# DEBUGSS_WRAP0_ROM_TABLE_0_1 register map
Vendor: Texas Instruments
Peripheral module from a debugger description file (folder am62P).
Registers are 32-bit, read-only, reset values left out (the file's numbers can be read two ways) unless marked. A register's access mark holds for its fields unless they carry their own. Offsets are as the file gives them; lines under a group give offsets from that group; [hi:lo] are bit positions; {n}, {i} and the like mark numbered series; 'fields as' and 'values as' point back to an identical list; <NAME> marks a mode.

## DEBUGSS_WRAP0_ROM_TABLE_0_1
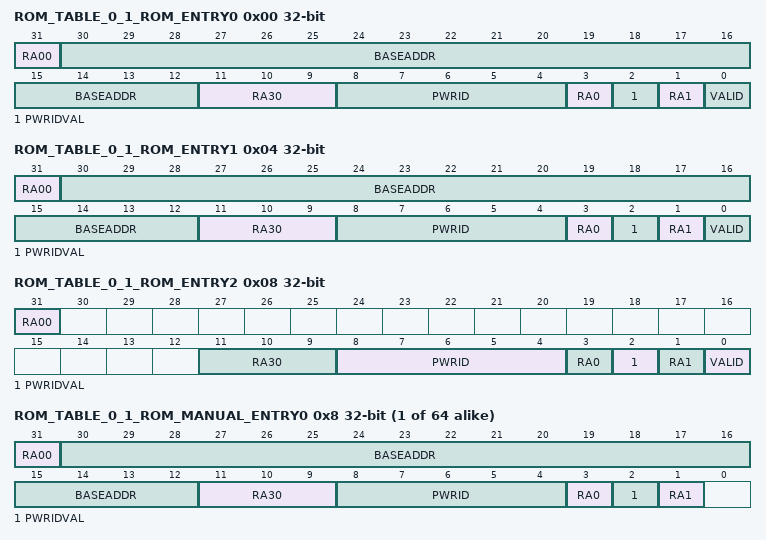
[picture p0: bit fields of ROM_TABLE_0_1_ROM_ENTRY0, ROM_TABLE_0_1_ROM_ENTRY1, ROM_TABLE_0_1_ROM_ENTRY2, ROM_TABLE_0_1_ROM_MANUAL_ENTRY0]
0x00 ROM_TABLE_0_1_ROM_ENTRY0
  [31] RA00 — always read as 0
  [30:12] BASEADDR — Component base address
  [11:9] RA30 — always read as 0
  [8:4] PWRID — always read as 0
  [3] RA0 — always read as 0
  [2] PWRIDVAL — power id valid
  [1] RA1 — always read as 1
  [0] VALID — Component present,1, or not present,0, status bit
0x04 ROM_TABLE_0_1_ROM_ENTRY1
  fields as ROM_TABLE_0_1_ROM_ENTRY0
0x08 ROM_TABLE_0_1_ROM_ENTRY2
  [31] RA00 — always read as 0
  [11:9] RA30 — always read as 0
  [8:4] PWRID — always read as 0
  [3] RA0 — always read as 0
  [2] PWRIDVAL — power id valid
  [1] RA1 — always read as 1
  [0] VALID — Component present,1, or not present,0, status bit
{0x8+4i} ROM_TABLE_0_1_ROM_MANUAL_ENTRY{i} (i=0..63)
  [31] RA00 — always read as 0
  [30:12] BASEADDR — Component base address
  [11:9] RA30 — always read as 0
  [8:4] PWRID — always read as 0
  [3] RA0 — always read as 0
  [2] PWRIDVAL — power id valid
  [1] RA1 — always read as 1
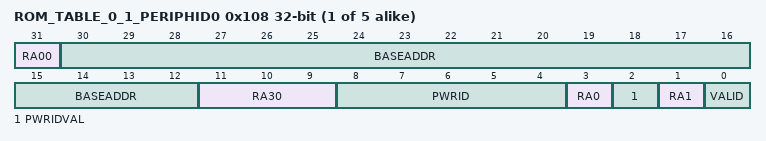
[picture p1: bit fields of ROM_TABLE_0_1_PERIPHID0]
{0x108+4i} ROM_TABLE_0_1_PERIPHID{i} (i=0..4)
  fields as ROM_TABLE_0_1_ROM_ENTRY0
0x3FC ROM_TABLE_0_1_COMPID{i} (i=0..3)
  [31:0] VAR — Component id{i}
